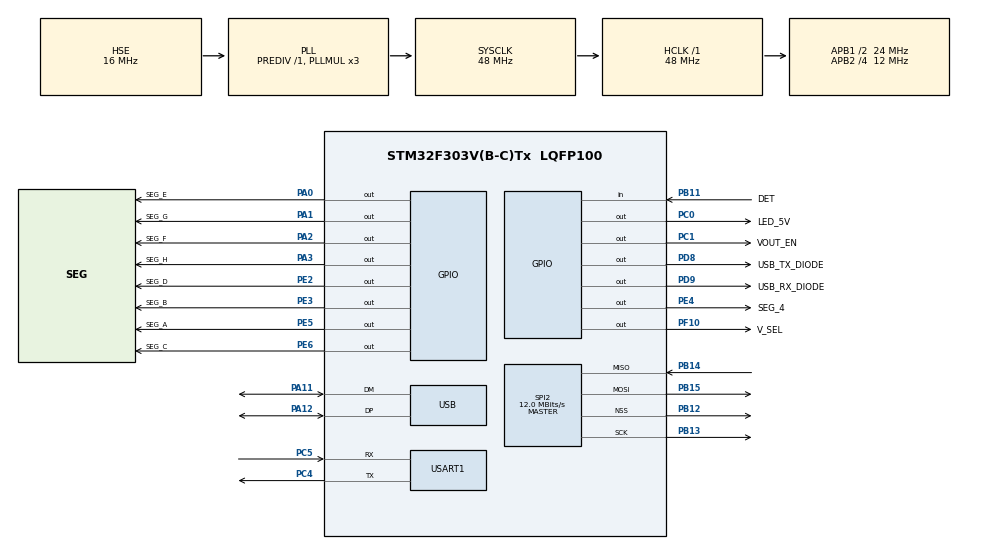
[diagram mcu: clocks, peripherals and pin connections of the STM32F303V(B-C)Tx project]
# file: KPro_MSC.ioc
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Mcu.Family=STM32F3
Mcu.Name=STM32F303V(B-C)Tx
Mcu.Package=LQFP100
NVIC.PriorityGroup=NVIC_PRIORITYGROUP_4
NVIC.USB_LP_CAN_RX0_IRQn=true\:0\:0\:false\:false\:true\:false\:true
PA0.GPIO_Label=SEG_E
PA0.Signal=GPIO_Output
PA1.GPIO_Label=SEG_G
PA1.Signal=GPIO_Output
PA11.Mode=Device
PA11.Signal=USB_DM
PA12.Mode=Device
PA12.Signal=USB_DP
PA13.Mode=Serial_Wire
PA13.Signal=SYS_JTMS-SWDIO
PA14.Mode=Serial_Wire
PA14.Signal=SYS_JTCK-SWCLK
PA2.GPIO_Label=SEG_F
PA2.Signal=GPIO_Output
PA3.GPIO_Label=SEG_H
PA3.Signal=GPIO_Output
PB11.GPIO_Label=DET
PB11.Signal=GPIO_Input
PB12.Mode=NSS_Signal_Hard_Output
PB12.Signal=SPI2_NSS
PB13.Mode=Full_Duplex_Master
PB13.Signal=SPI2_SCK
PB14.Mode=Full_Duplex_Master
PB14.Signal=SPI2_MISO
PB15.Mode=Full_Duplex_Master
PB15.Signal=SPI2_MOSI
PC0.GPIO_Label=LED_5V
PC0.Signal=GPIO_Output
PC1.GPIO_Label=VOUT_EN
PC1.Signal=GPIO_Output
PC4.Mode=Asynchronous
PC4.Signal=USART1_TX
PC5.Mode=Asynchronous
PC5.Signal=USART1_RX
PD8.GPIO_Label=USB_TX_DIODE
PD8.Signal=GPIO_Output
PD9.GPIO_Label=USB_RX_DIODE
PD9.Signal=GPIO_Output
PE2.GPIO_Label=SEG_D
PE2.Signal=GPIO_Output
PE3.GPIO_Label=SEG_B
PE3.Signal=GPIO_Output
PE4.GPIO_Label=SEG_4
PE4.Signal=GPIO_Output
PE5.GPIO_Label=SEG_A
PE5.Signal=GPIO_Output
PE6.GPIO_Label=SEG_C
PE6.Signal=GPIO_Output
PF0-OSC_IN.Mode=HSE-External-Clock-Source
PF0-OSC_IN.Signal=RCC_OSC_IN
PF10.GPIO_Label=V_SEL
PF10.Signal=GPIO_Output
ProjectManager.HeapSize=0x200
ProjectManager.StackSize=0x400
ProjectManager.TargetToolchain=STM32CubeIDE
RCC.AHBFreq_Value=48000000
RCC.APB1CLKDivider=RCC_HCLK_DIV2
RCC.APB1Freq_Value=24000000
RCC.APB1TimFreq_Value=48000000
RCC.APB2CLKDivider=RCC_HCLK_DIV4
RCC.APB2Freq_Value=12000000
RCC.APB2TimFreq_Value=24000000
RCC.CortexFreq_Value=48000000
RCC.HCLKFreq_Value=48000000
RCC.HSE_VALUE=16000000
RCC.HSI_VALUE=8000000
RCC.LSE_VALUE=32768
RCC.PLLMUL=RCC_PLL_MUL3
RCC.SYSCLKFreq_VALUE=48000000
RCC.SYSCLKSourceVirtual=RCC_SYSCLKSOURCE_PLLCLK
RCC.USBFreq_Value=48000000
SPI2.BaudRatePrescaler=SPI_BAUDRATEPRESCALER_2
SPI2.CalculateBaudRate=12.0 MBits/s
SPI2.Direction=SPI_DIRECTION_2LINES
SPI2.Mode=SPI_MODE_MASTER
SPI2.VirtualNSS=VM_NSSHARD
SPI2.VirtualType=VM_MASTER
USART1.VirtualMode-Asynchronous=VM_ASYNC
USB_DEVICE.CLASS_NAME_FS=MSC
USB_DEVICE.VirtualMode=Msc
USB_DEVICE.VirtualModeFS=Msc_FS
VP_USB_DEVICE_VS_USB_DEVICE_MSC_FS.Mode=MSC_FS
board=custom

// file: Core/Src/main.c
/* USER CODE BEGIN Header */
/**
  ******************************************************************************
  * @file           : main.c
  * @brief          : Main program body
  ******************************************************************************
  * @attention
  *
  * <h2><center>&copy; Copyright (c) 2021 STMicroelectronics.
  * All rights reserved.</center></h2>
  *
  * This software component is licensed by ST under Ultimate Liberty license
  * SLA0044, the "License"; You may not use this file except in compliance with
  * the License. You may obtain a copy of the License at:
  *                             www.st.com/SLA0044
  *
  ******************************************************************************
  */
/* USER CODE END Header */
#include "main.h"
#include "usb_device.h"

SPI_HandleTypeDef hspi2;

UART_HandleTypeDef huart1;

void SystemClock_Config(void);
static void MX_GPIO_Init(void);
static void MX_SPI2_Init(void);
static void MX_USART1_UART_Init(void);

int main(void)
{

  /* MCU Configuration--------------------------------------------------------*/

  /* Reset of all peripherals, Initializes the Flash interface and the Systick. */
  HAL_Init();

  /* Configure the system clock */
  SystemClock_Config();

  /* Initialize all configured peripherals */
  MX_GPIO_Init();
  MX_SPI2_Init();
  MX_USART1_UART_Init();
  MX_USB_DEVICE_Init();

  /* Infinite loop */
  while (1)
  {

    /* USER CODE BEGIN 3 */
	  HAL_GPIO_TogglePin(USB_RX_DIODE_GPIO_Port, USB_RX_DIODE_Pin);
	  HAL_Delay(1000);
  }
  /* USER CODE END 3 */
}

void SystemClock_Config(void)
{
  RCC_OscInitTypeDef RCC_OscInitStruct = {0};
  RCC_ClkInitTypeDef RCC_ClkInitStruct = {0};
  RCC_PeriphCLKInitTypeDef PeriphClkInit = {0};

  /** Initializes the RCC Oscillators according to the specified parameters
  * in the RCC_OscInitTypeDef structure.
  */
  RCC_OscInitStruct.OscillatorType = RCC_OSCILLATORTYPE_HSE;
  RCC_OscInitStruct.HSEState = RCC_HSE_BYPASS;
  RCC_OscInitStruct.HSEPredivValue = RCC_HSE_PREDIV_DIV1;
  RCC_OscInitStruct.HSIState = RCC_HSI_ON;
  RCC_OscInitStruct.PLL.PLLState = RCC_PLL_ON;
  RCC_OscInitStruct.PLL.PLLSource = RCC_PLLSOURCE_HSE;
  RCC_OscInitStruct.PLL.PLLMUL = RCC_PLL_MUL3;
  if (HAL_RCC_OscConfig(&RCC_OscInitStruct) != HAL_OK)
  {
    Error_Handler();
  }
  /** Initializes the CPU, AHB and APB buses clocks
  */
  RCC_ClkInitStruct.ClockType = RCC_CLOCKTYPE_HCLK|RCC_CLOCKTYPE_SYSCLK
                              |RCC_CLOCKTYPE_PCLK1|RCC_CLOCKTYPE_PCLK2;
  RCC_ClkInitStruct.SYSCLKSource = RCC_SYSCLKSOURCE_PLLCLK;
  RCC_ClkInitStruct.AHBCLKDivider = RCC_SYSCLK_DIV1;
  RCC_ClkInitStruct.APB1CLKDivider = RCC_HCLK_DIV2;
  RCC_ClkInitStruct.APB2CLKDivider = RCC_HCLK_DIV4;

  if (HAL_RCC_ClockConfig(&RCC_ClkInitStruct, FLASH_LATENCY_1) != HAL_OK)
  {
    Error_Handler();
  }
  PeriphClkInit.PeriphClockSelection = RCC_PERIPHCLK_USB|RCC_PERIPHCLK_USART1;
  PeriphClkInit.Usart1ClockSelection = RCC_USART1CLKSOURCE_PCLK2;
  PeriphClkInit.USBClockSelection = RCC_USBCLKSOURCE_PLL;
  if (HAL_RCCEx_PeriphCLKConfig(&PeriphClkInit) != HAL_OK)
  {
    Error_Handler();
  }
}

static void MX_SPI2_Init(void)
{

  /* SPI2 parameter configuration*/
  hspi2.Instance = SPI2;
  hspi2.Init.Mode = SPI_MODE_MASTER;
  hspi2.Init.Direction = SPI_DIRECTION_2LINES;
  hspi2.Init.DataSize = SPI_DATASIZE_4BIT;
  hspi2.Init.CLKPolarity = SPI_POLARITY_LOW;
  hspi2.Init.CLKPhase = SPI_PHASE_1EDGE;
  hspi2.Init.NSS = SPI_NSS_HARD_OUTPUT;
  hspi2.Init.BaudRatePrescaler = SPI_BAUDRATEPRESCALER_2;
  hspi2.Init.FirstBit = SPI_FIRSTBIT_MSB;
  hspi2.Init.TIMode = SPI_TIMODE_DISABLE;
  hspi2.Init.CRCCalculation = SPI_CRCCALCULATION_DISABLE;
  hspi2.Init.CRCPolynomial = 7;
  hspi2.Init.CRCLength = SPI_CRC_LENGTH_DATASIZE;
  hspi2.Init.NSSPMode = SPI_NSS_PULSE_ENABLE;
  if (HAL_SPI_Init(&hspi2) != HAL_OK)
  {
    Error_Handler();
  }

}

static void MX_USART1_UART_Init(void)
{

  huart1.Instance = USART1;
  huart1.Init.BaudRate = 38400;
  huart1.Init.WordLength = UART_WORDLENGTH_8B;
  huart1.Init.StopBits = UART_STOPBITS_1;
  huart1.Init.Parity = UART_PARITY_NONE;
  huart1.Init.Mode = UART_MODE_TX_RX;
  huart1.Init.HwFlowCtl = UART_HWCONTROL_NONE;
  huart1.Init.OverSampling = UART_OVERSAMPLING_16;
  huart1.Init.OneBitSampling = UART_ONE_BIT_SAMPLE_DISABLE;
  huart1.AdvancedInit.AdvFeatureInit = UART_ADVFEATURE_NO_INIT;
  if (HAL_UART_Init(&huart1) != HAL_OK)
  {
    Error_Handler();
  }

}

static void MX_GPIO_Init(void)
{
  GPIO_InitTypeDef GPIO_InitStruct = {0};

  /* GPIO Ports Clock Enable */
  __HAL_RCC_GPIOE_CLK_ENABLE();
  __HAL_RCC_GPIOF_CLK_ENABLE();
  __HAL_RCC_GPIOC_CLK_ENABLE();
  __HAL_RCC_GPIOA_CLK_ENABLE();
  __HAL_RCC_GPIOB_CLK_ENABLE();
  __HAL_RCC_GPIOD_CLK_ENABLE();

  /*Configure GPIO pin Output Level */
  HAL_GPIO_WritePin(GPIOE, SEG_D_Pin|SEG_B_Pin|SEG_4_Pin|SEG_A_Pin
                          |SEG_C_Pin, GPIO_PIN_RESET);

  /*Configure GPIO pin Output Level */
  HAL_GPIO_WritePin(V_SEL_GPIO_Port, V_SEL_Pin, GPIO_PIN_RESET);

  /*Configure GPIO pin Output Level */
  HAL_GPIO_WritePin(GPIOC, LED_5V_Pin|VOUT_EN_Pin, GPIO_PIN_RESET);

  /*Configure GPIO pin Output Level */
  HAL_GPIO_WritePin(GPIOA, SEG_E_Pin|SEG_G_Pin|SEG_F_Pin|SEG_H_Pin, GPIO_PIN_RESET);

  /*Configure GPIO pin Output Level */
  HAL_GPIO_WritePin(GPIOD, USB_TX_DIODE_Pin|USB_RX_DIODE_Pin, GPIO_PIN_RESET);

  /*Configure GPIO pins : SEG_D_Pin SEG_B_Pin SEG_4_Pin SEG_A_Pin
                           SEG_C_Pin */
  GPIO_InitStruct.Pin = SEG_D_Pin|SEG_B_Pin|SEG_4_Pin|SEG_A_Pin
                          |SEG_C_Pin;
  GPIO_InitStruct.Mode = GPIO_MODE_OUTPUT_PP;
  GPIO_InitStruct.Pull = GPIO_NOPULL;
  GPIO_InitStruct.Speed = GPIO_SPEED_FREQ_LOW;
  HAL_GPIO_Init(GPIOE, &GPIO_InitStruct);

  /*Configure GPIO pin : V_SEL_Pin */
  GPIO_InitStruct.Pin = V_SEL_Pin;
  GPIO_InitStruct.Mode = GPIO_MODE_OUTPUT_PP;
  GPIO_InitStruct.Pull = GPIO_NOPULL;
  GPIO_InitStruct.Speed = GPIO_SPEED_FREQ_LOW;
  HAL_GPIO_Init(V_SEL_GPIO_Port, &GPIO_InitStruct);

  /*Configure GPIO pins : LED_5V_Pin VOUT_EN_Pin */
  GPIO_InitStruct.Pin = LED_5V_Pin|VOUT_EN_Pin;
  GPIO_InitStruct.Mode = GPIO_MODE_OUTPUT_PP;
  GPIO_InitStruct.Pull = GPIO_NOPULL;
  GPIO_InitStruct.Speed = GPIO_SPEED_FREQ_LOW;
  HAL_GPIO_Init(GPIOC, &GPIO_InitStruct);

  /*Configure GPIO pins : SEG_E_Pin SEG_G_Pin SEG_F_Pin SEG_H_Pin */
  GPIO_InitStruct.Pin = SEG_E_Pin|SEG_G_Pin|SEG_F_Pin|SEG_H_Pin;
  GPIO_InitStruct.Mode = GPIO_MODE_OUTPUT_PP;
  GPIO_InitStruct.Pull = GPIO_NOPULL;
  GPIO_InitStruct.Speed = GPIO_SPEED_FREQ_LOW;
  HAL_GPIO_Init(GPIOA, &GPIO_InitStruct);

  /*Configure GPIO pin : DET_Pin */
  GPIO_InitStruct.Pin = DET_Pin;
  GPIO_InitStruct.Mode = GPIO_MODE_INPUT;
  GPIO_InitStruct.Pull = GPIO_NOPULL;
  HAL_GPIO_Init(DET_GPIO_Port, &GPIO_InitStruct);

  /*Configure GPIO pins : USB_TX_DIODE_Pin USB_RX_DIODE_Pin */
  GPIO_InitStruct.Pin = USB_TX_DIODE_Pin|USB_RX_DIODE_Pin;
  GPIO_InitStruct.Mode = GPIO_MODE_OUTPUT_PP;
  GPIO_InitStruct.Pull = GPIO_NOPULL;
  GPIO_InitStruct.Speed = GPIO_SPEED_FREQ_LOW;
  HAL_GPIO_Init(GPIOD, &GPIO_InitStruct);

}

void Error_Handler(void)
{
}

/************************ (C) COPYRIGHT STMicroelectronics *****END OF FILE****/
